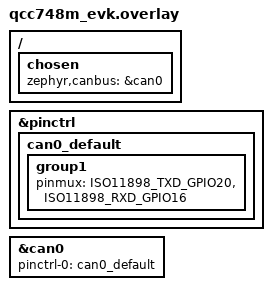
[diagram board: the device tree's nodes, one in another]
/*
 * Copyright (c) 2026 Qualcomm Technologies, Inc. and/or its subsidiaries
 * SPDX-License-Identifier: BSD-3-Clause
 */

/ {
	chosen {
		zephyr,canbus = &can0;
	};
};

&pinctrl {
	can0_default: can0_default {
		group1 {
			pinmux = <ISO11898_TXD_GPIO20>,
				<ISO11898_RXD_GPIO16>;
		};
	};
};

&can0 {
	status = "okay";
	pinctrl-0 = <&can0_default>;
	pinctrl-names = "default";
};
